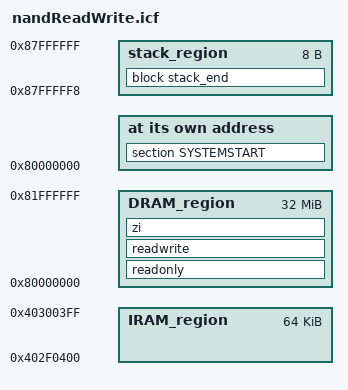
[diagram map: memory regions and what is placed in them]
/*
* Copyright (C) 2010 Texas Instruments Incorporated - http://www.ti.com/ 
*/
/* 
*  Redistribution and use in source and binary forms, with or without 
*  modification, are permitted provided that the following conditions 
*  are met:
*
*    Redistributions of source code must retain the above copyright 
*    notice, this list of conditions and the following disclaimer.
*
*    Redistributions in binary form must reproduce the above copyright
*    notice, this list of conditions and the following disclaimer in the 
*    documentation and/or other materials provided with the   
*    distribution.
*
*    Neither the name of Texas Instruments Incorporated nor the names of
*    its contributors may be used to endorse or promote products derived
*    from this software without specific prior written permission.
*
*  THIS SOFTWARE IS PROVIDED BY THE COPYRIGHT HOLDERS AND CONTRIBUTORS 
*  "AS IS" AND ANY EXPRESS OR IMPLIED WARRANTIES, INCLUDING, BUT NOT 
*  LIMITED TO, THE IMPLIED WARRANTIES OF MERCHANTABILITY AND FITNESS FOR
*  A PARTICULAR PURPOSE ARE DISCLAIMED. IN NO EVENT SHALL THE COPYRIGHT 
*  OWNER OR CONTRIBUTORS BE LIABLE FOR ANY DIRECT, INDIRECT, INCIDENTAL, 
*  SPECIAL, EXEMPLARY, OR CONSEQUENTIAL DAMAGES (INCLUDING, BUT NOT 
*  LIMITED TO, PROCUREMENT OF SUBSTITUTE GOODS OR SERVICES; LOSS OF USE,
*  DATA, OR PROFITS; OR BUSINESS INTERRUPTION) HOWEVER CAUSED AND ON ANY
*  THEORY OF LIABILITY, WHETHER IN CONTRACT, STRICT LIABILITY, OR TORT 
*  (INCLUDING NEGLIGENCE OR OTHERWISE) ARISING IN ANY WAY OUT OF THE USE 
*  OF THIS SOFTWARE, EVEN IF ADVISED OF THE POSSIBILITY OF SUCH DAMAGE.
*
*/


define memory mem with size = 4G;

/* Define internal RAM region */
define region IRAM_region = mem:[from 0x402F0400 size 0x10000];

/* Define internal DRAM region */
define region DRAM_region = mem:[from 0x80000000 size 0x2000000];

/* Define Stack */
define region stack_region = mem:[from 0x87FFFFF8 size 0x08];

define block stack_end  with alignment = 8, size =0  { };

place at address mem:0x80000000 { section SYSTEMSTART };
place in DRAM_region   { readonly };
place in DRAM_region   { readwrite };
place in DRAM_region   { zi };
place in stack_region  { block stack_end};
